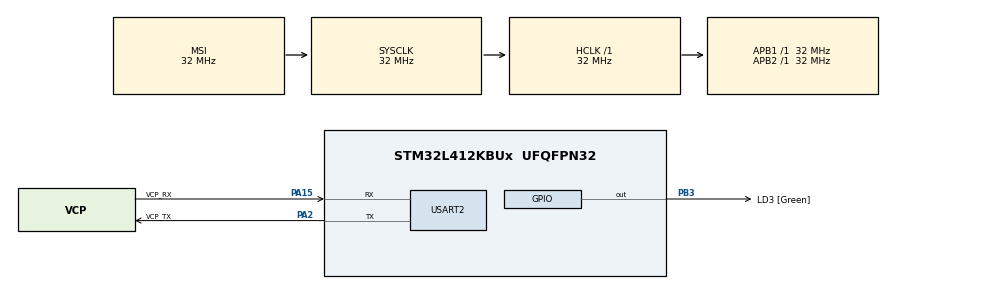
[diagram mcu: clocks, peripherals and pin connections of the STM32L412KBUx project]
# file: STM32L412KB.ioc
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Dma.Request0=USART2_RX
Dma.USART2_RX.0.Direction=DMA_PERIPH_TO_MEMORY
Dma.USART2_RX.0.Instance=DMA1_Channel6
Dma.USART2_RX.0.MemDataAlignment=DMA_MDATAALIGN_BYTE
Dma.USART2_RX.0.MemInc=DMA_MINC_ENABLE
Dma.USART2_RX.0.Mode=DMA_CIRCULAR
Dma.USART2_RX.0.PeriphDataAlignment=DMA_PDATAALIGN_BYTE
Dma.USART2_RX.0.PeriphInc=DMA_PINC_DISABLE
Dma.USART2_RX.0.Priority=DMA_PRIORITY_LOW
Mcu.Family=STM32L4
Mcu.Name=STM32L412KBUx
Mcu.Package=UFQFPN32
NVIC.DMA1_Channel6_IRQn=true\:0\:0\:false\:false\:true\:false\:true
NVIC.PriorityGroup=NVIC_PRIORITYGROUP_4
NVIC.RTC_Alarm_IRQn=true\:0\:0\:false\:false\:true\:true\:true
PA0-CK_IN.Mode=HSE-External-Clock-Source-for-LittleOrca
PA0-CK_IN.Signal=RCC_CK_IN
PA13\ (JTMS/SWDIO).GPIO_Label=SWDIO
PA13\ (JTMS/SWDIO).Mode=Serial_Wire
PA13\ (JTMS/SWDIO).Signal=SYS_JTMS-SWDIO
PA14\ (JTCK/SWCLK).GPIO_Label=SWCLK
PA14\ (JTCK/SWCLK).Mode=Serial_Wire
PA14\ (JTCK/SWCLK).Signal=SYS_JTCK-SWCLK
PA15\ (JTDI).GPIO_Label=VCP_RX
PA15\ (JTDI).Mode=Asynchronous
PA15\ (JTDI).Signal=USART2_RX
PA2.GPIO_Label=VCP_TX
PA2.Mode=Asynchronous
PA2.Signal=USART2_TX
PB3\ (JTDO/TRACESWO).GPIO_Label=LD3 [Green]
PB3\ (JTDO/TRACESWO).Signal=GPIO_Output
PC14-OSC32_IN\ (PC14).Mode=LSE-External-Oscillator
PC14-OSC32_IN\ (PC14).Signal=RCC_OSC32_IN
PC15-OSC32_OUT\ (PC15).Mode=LSE-External-Oscillator
PC15-OSC32_OUT\ (PC15).Signal=RCC_OSC32_OUT
ProjectManager.HeapSize=0x200
ProjectManager.StackSize=0x400
ProjectManager.TargetToolchain=EWARM V8.32
RCC.ADCFreq_Value=32000000
RCC.AHBFreq_Value=32000000
RCC.APB1Freq_Value=32000000
RCC.APB1TimFreq_Value=32000000
RCC.APB2Freq_Value=32000000
RCC.APB2TimFreq_Value=32000000
RCC.CortexFreq_Value=32000000
RCC.FLatency=FLASH_LATENCY_1
RCC.HCLKFreq_Value=32000000
RCC.HSE_VALUE=8000000
RCC.HSI48_VALUE=48000000
RCC.HSICalibrationValue=16
RCC.HSI_VALUE=16000000
RCC.LSE_Drive_Capability=RCC_LSEDRIVE_LOW
RCC.MSIClockRange=RCC_MSIRANGE_10
RCC.MSI_VALUE=32000000
RCC.SYSCLKFreq_VALUE=32000000
RCC.USBFreq_Value=32000000
RCC.VCOOutputFreq_Value=256000000
RTC.Alarm=RTC_ALARM_A
RTC.AsynchPrediv=124
USART2.VirtualMode-Asynchronous=VM_ASYNC
VP_RTC_VS_RTC_Activate.Mode=RTC_Enabled
VP_RTC_VS_RTC_Alarm_A_Intern.Mode=Alarm A
VP_RTC_VS_RTC_Calendar.Mode=RTC_Calendar
board=NUCLEO-L412KB

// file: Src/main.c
/* USER CODE BEGIN Header */
/**
  ******************************************************************************
  * @file           : main.c
  * @brief          : Main program body
  ******************************************************************************
  * @attention
  *
  * <h2><center>&copy; Copyright (c) 2019 STMicroelectronics.
  * All rights reserved.</center></h2>
  *
  * This software component is licensed by ST under BSD 3-Clause license,
  * the "License"; You may not use this file except in compliance with the
  * License. You may obtain a copy of the License at:
  *                        opensource.org/licenses/BSD-3-Clause
  *
  ******************************************************************************
  */
/* USER CODE END Header */

#include "main.h"
#include "dma.h"
#include "rtc.h"
#include "usart.h"
#include "gpio.h"

/* USER CODE BEGIN Includes */
#include "user.h"

/* USER CODE END Includes */

void SystemClock_Config(void);

int main(void)
{

  /* MCU Configuration--------------------------------------------------------*/

  /* Reset of all peripherals, Initializes the Flash interface and the Systick. */
  HAL_Init();

  /* Configure the system clock */
  SystemClock_Config();

  /* Initialize all configured peripherals */
  MX_GPIO_Init();
  MX_DMA_Init();
  MX_USART2_UART_Init();
  MX_RTC_Init();
  /* USER CODE BEGIN 2 */
  user_start();

  /* USER CODE END 2 */

  /* Infinite loop */
  /* USER CODE BEGIN WHILE */
  while (1)
  {
		user_while();
    /* USER CODE END WHILE */

  }
}

void SystemClock_Config(void)
{
  RCC_OscInitTypeDef RCC_OscInitStruct = {0};
  RCC_ClkInitTypeDef RCC_ClkInitStruct = {0};
  RCC_PeriphCLKInitTypeDef PeriphClkInit = {0};

  /** Configure LSE Drive Capability
  */
  HAL_PWR_EnableBkUpAccess();
  __HAL_RCC_LSEDRIVE_CONFIG(RCC_LSEDRIVE_LOW);
  /** Configure the main internal regulator output voltage
  */
  if (HAL_PWREx_ControlVoltageScaling(PWR_REGULATOR_VOLTAGE_SCALE1) != HAL_OK)
  {
    Error_Handler();
  }
  /** Initializes the CPU, AHB and APB busses clocks
  */
  RCC_OscInitStruct.OscillatorType = RCC_OSCILLATORTYPE_LSI|RCC_OSCILLATORTYPE_LSE
                              |RCC_OSCILLATORTYPE_MSI;
  RCC_OscInitStruct.LSEState = RCC_LSE_ON;
  RCC_OscInitStruct.LSIState = RCC_LSI_ON;
  RCC_OscInitStruct.MSIState = RCC_MSI_ON;
  RCC_OscInitStruct.MSICalibrationValue = 0;
  RCC_OscInitStruct.MSIClockRange = RCC_MSIRANGE_10;
  RCC_OscInitStruct.PLL.PLLState = RCC_PLL_NONE;
  if (HAL_RCC_OscConfig(&RCC_OscInitStruct) != HAL_OK)
  {
    Error_Handler();
  }
  /** Initializes the CPU, AHB and APB busses clocks
  */
  RCC_ClkInitStruct.ClockType = RCC_CLOCKTYPE_HCLK|RCC_CLOCKTYPE_SYSCLK
                              |RCC_CLOCKTYPE_PCLK1|RCC_CLOCKTYPE_PCLK2;
  RCC_ClkInitStruct.SYSCLKSource = RCC_SYSCLKSOURCE_MSI;
  RCC_ClkInitStruct.AHBCLKDivider = RCC_SYSCLK_DIV1;
  RCC_ClkInitStruct.APB1CLKDivider = RCC_HCLK_DIV1;
  RCC_ClkInitStruct.APB2CLKDivider = RCC_HCLK_DIV1;

  if (HAL_RCC_ClockConfig(&RCC_ClkInitStruct, FLASH_LATENCY_1) != HAL_OK)
  {
    Error_Handler();
  }
  PeriphClkInit.PeriphClockSelection = RCC_PERIPHCLK_RTC|RCC_PERIPHCLK_USART2;
  PeriphClkInit.Usart2ClockSelection = RCC_USART2CLKSOURCE_PCLK1;
  PeriphClkInit.RTCClockSelection = RCC_RTCCLKSOURCE_LSI;
  if (HAL_RCCEx_PeriphCLKConfig(&PeriphClkInit) != HAL_OK)
  {
    Error_Handler();
  }
  /** Enable MSI Auto calibration
  */
  HAL_RCCEx_EnableMSIPLLMode();
}

void Error_Handler(void)
{
}

/************************ (C) COPYRIGHT STMicroelectronics *****END OF FILE****/
